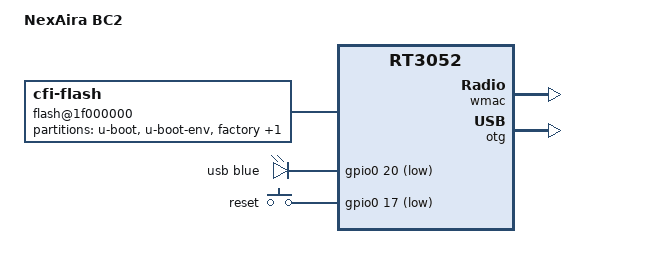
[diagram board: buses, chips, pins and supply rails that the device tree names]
#include "rt3050.dtsi"

#include <dt-bindings/gpio/gpio.h>
#include <dt-bindings/input/input.h>
#include <dt-bindings/leds/common.h>

/ {
	compatible = "nexaira,bc2", "ralink,rt3052-soc";
	model = "NexAira BC2";

	flash@1f000000 {
		compatible = "cfi-flash";
		reg = <0x1f000000 0x800000>;
		bank-width = <2>;
		device-width = <2>;

		partitions {
			compatible = "fixed-partitions";
			#address-cells = <1>;
			#size-cells = <1>;

			partition@0 {
				label = "u-boot";
				reg = <0x0 0x30000>;
				read-only;
			};

			partition@30000 {
				label = "u-boot-env";
				reg = <0x30000 0x10000>;
				read-only;
			};

			partition@40000 {
				label = "factory";
				reg = <0x40000 0x10000>;
				read-only;

				nvmem-layout {
					compatible = "fixed-layout";
					#address-cells = <1>;
					#size-cells = <1>;

					eeprom_factory_0: eeprom@0 {
						reg = <0x0 0x200>;
					};

					macaddr_factory_4: macaddr@4 {
						reg = <0x4 0x6>;
					};
				};
			};

			partition@50000 {
				compatible = "denx,uimage";
				label = "firmware";
				reg = <0x50000 0x7b0000>;
			};
		};
	};

	leds {
		compatible = "gpio-leds";

		usb {
			function = LED_FUNCTION_USB;
			color = <LED_COLOR_ID_BLUE>;
			gpios = <&gpio0 20 GPIO_ACTIVE_LOW>;
			trigger-sources = <&otg_port1>;
			linux,default-trigger = "usbport";
		};
	};

	keys {
		compatible = "gpio-keys";

		reset {
			label = "reset";
			gpios = <&gpio0 17 GPIO_ACTIVE_LOW>;
			linux,code = <KEY_RESTART>;
		};
	};
};

&state_default {
	gpio {
		groups = "spi", "i2c", "jtag", "rgmii", "mdio", "uartf";
		function = "gpio";
	};
};

&ethernet {
	nvmem-cells = <&macaddr_factory_4>;
	nvmem-cell-names = "mac-address";
};

&esw {
	mediatek,portmap = <0x2f>;
};

&wmac {
	nvmem-cells = <&eeprom_factory_0>;
	nvmem-cell-names = "eeprom";
};

&otg {
	status = "okay";
};
